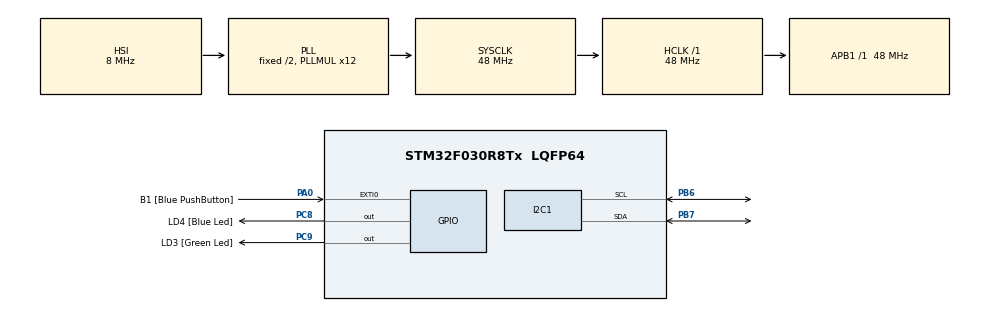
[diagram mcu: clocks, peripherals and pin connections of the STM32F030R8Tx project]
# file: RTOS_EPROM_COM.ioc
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FREERTOS.Tasks01=defaultTask,0,128,StartDefaultTask,Default,NULL,Dynamic,NULL,NULL
FREERTOS.configUSE_PREEMPTION=0
Mcu.Family=STM32F0
Mcu.Name=STM32F030R8Tx
Mcu.Package=LQFP64
NVIC.I2C1_IRQn=true\:3\:0\:false\:false\:true\:true\:true\:true
PA0.GPIO_Label=B1 [Blue PushButton]
PA0.GPIO_ModeDefaultEXTI=GPIO_MODE_EVT_RISING
PA0.Signal=GPXTI0
PA13.GPIO_Label=SWDIO
PA13.Mode=Serial_Wire
PA13.Signal=SYS_SWDIO
PA14.GPIO_Label=SWCLK
PA14.Mode=Serial_Wire
PA14.Signal=SYS_SWCLK
PB6.Mode=I2C
PB6.Signal=I2C1_SCL
PB7.Mode=I2C
PB7.Signal=I2C1_SDA
PC8.GPIO_Label=LD4 [Blue Led]
PC8.Signal=GPIO_Output
PC9.GPIO_Label=LD3 [Green Led]
PC9.Signal=GPIO_Output
ProjectManager.HeapSize=0x200
ProjectManager.StackSize=0x400
ProjectManager.TargetToolchain=STM32CubeIDE
RCC.AHBFreq_Value=48000000
RCC.APB1Freq_Value=48000000
RCC.APB1TimFreq_Value=48000000
RCC.HCLKFreq_Value=48000000
RCC.PLLMUL=RCC_PLL_MUL12
RCC.SYSCLKFreq_VALUE=48000000
RCC.SYSCLKSource=RCC_SYSCLKSOURCE_PLLCLK
VP_FREERTOS_VS_CMSIS_V1.Mode=CMSIS_V1
board=STM32F0308-DISCO

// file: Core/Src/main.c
/**
  ******************************************************************************
  * @file           : main.c
  * @brief          : Main program body
  ******************************************************************************
  * @attention
  *
  * <h2><center>&copy; Copyright (c) 2020 STMicroelectronics.
  * All rights reserved.</center></h2>
  *
  * This software component is licensed by ST under BSD 3-Clause license,
  * the "License"; You may not use this file except in compliance with the
  * License. You may obtain a copy of the License at:
  *                        opensource.org/licenses/BSD-3-Clause
  *
  ******************************************************************************
  */

#include "main.h"
#include "cmsis_os.h"

I2C_HandleTypeDef hi2c1;

osThreadId defaultTaskHandle;
/* USER CODE BEGIN PV */
osThreadId defaultTaskHandle1;
osThreadId defaultTaskHandle2;
/* USER CODE END PV */

void SystemClock_Config(void);
static void MX_GPIO_Init(void);
static void MX_I2C1_Init(void);
void StartDefaultTask(void const * argument);
void i2c_write(void);
void i2c_read(void);

uint8_t data[3] = {1,2,3};
uint8_t RX_data[3] = {0};
uint8_t data1[3] = {4,5,6};
uint8_t RX_data1[3] = {0};

osMutexId mutex_id;

int main(void)
{

  /* MCU Configuration--------------------------------------------------------*/

  /* Reset of all peripherals, Initializes the Flash interface and the Systick. */
  HAL_Init();

  /* Configure the system clock */
  SystemClock_Config();

  /* Initialize all configured peripherals */
  MX_GPIO_Init();
  MX_I2C1_Init();

  /* add mutexes, ... */
  osMutexDef(mutex);
  //osMutexDef_t *mutex;
  mutex_id = osMutexCreate(osMutex(mutex));

  osThreadDef(task1, i2c_write, osPriorityNormal, 0, 128);
  defaultTaskHandle1 = osThreadCreate(osThread(task1), NULL);

  osThreadDef(task2, i2c_read, osPriorityNormal, 0, 128);
  defaultTaskHandle2 = osThreadCreate(osThread(task2), NULL);

  /* Start scheduler */
  osKernelStart();

  while (1)
  {
  }

}

void i2c_write()
{
	while(1)
	{
	osMutexWait(mutex_id, 300);

	 if (HAL_I2C_Mem_Write_IT(&hi2c1, (uint16_t)0xa0, 0x10, 1, data,3)!= HAL_OK)
	 {

		 Error_Handler();
	 }
	HAL_Delay(1000);

	if (HAL_I2C_Mem_Write_IT(&hi2c1, (uint16_t)0xa0, 0x30, 1, data1,3)!= HAL_OK)
	{
		 Error_Handler();
	}

	osMutexRelease(mutex_id);
	}

}

void i2c_read()
{
	while(1)
	{
	osMutexWait(mutex_id, 300);
	if (HAL_I2C_Mem_Read_IT(&hi2c1, (uint16_t)0xa1, 0x10, 1, RX_data,3)!= HAL_OK)
	{
		 Error_Handler();
	}
	HAL_Delay(1000);

	if (HAL_I2C_Mem_Read_IT(&hi2c1, (uint16_t)0xa1, 0x30, 1, RX_data1,3)!= HAL_OK)
	{
		 Error_Handler();
	}
	osMutexRelease(mutex_id);
	}
}

void SystemClock_Config(void)
{
  RCC_OscInitTypeDef RCC_OscInitStruct = {0};
  RCC_ClkInitTypeDef RCC_ClkInitStruct = {0};
  RCC_PeriphCLKInitTypeDef PeriphClkInit = {0};

  /** Initializes the CPU, AHB and APB busses clocks
  */
  RCC_OscInitStruct.OscillatorType = RCC_OSCILLATORTYPE_HSI;
  RCC_OscInitStruct.HSIState = RCC_HSI_ON;
  RCC_OscInitStruct.HSICalibrationValue = RCC_HSICALIBRATION_DEFAULT;
  RCC_OscInitStruct.PLL.PLLState = RCC_PLL_ON;
  RCC_OscInitStruct.PLL.PLLSource = RCC_PLLSOURCE_HSI;
  RCC_OscInitStruct.PLL.PLLMUL = RCC_PLL_MUL12;
  RCC_OscInitStruct.PLL.PREDIV = RCC_PREDIV_DIV1;
  if (HAL_RCC_OscConfig(&RCC_OscInitStruct) != HAL_OK)
  {
    Error_Handler();
  }
  /** Initializes the CPU, AHB and APB busses clocks
  */
  RCC_ClkInitStruct.ClockType = RCC_CLOCKTYPE_HCLK|RCC_CLOCKTYPE_SYSCLK
                              |RCC_CLOCKTYPE_PCLK1;
  RCC_ClkInitStruct.SYSCLKSource = RCC_SYSCLKSOURCE_PLLCLK;
  RCC_ClkInitStruct.AHBCLKDivider = RCC_SYSCLK_DIV1;
  RCC_ClkInitStruct.APB1CLKDivider = RCC_HCLK_DIV1;

  if (HAL_RCC_ClockConfig(&RCC_ClkInitStruct, FLASH_LATENCY_1) != HAL_OK)
  {
    Error_Handler();
  }
  PeriphClkInit.PeriphClockSelection = RCC_PERIPHCLK_I2C1;
  PeriphClkInit.I2c1ClockSelection = RCC_I2C1CLKSOURCE_HSI;
  if (HAL_RCCEx_PeriphCLKConfig(&PeriphClkInit) != HAL_OK)
  {
    Error_Handler();
  }
}

static void MX_I2C1_Init(void)
{

  hi2c1.Instance = I2C1;
  hi2c1.Init.Timing = 0x2000090E;
  hi2c1.Init.OwnAddress1 = 0;
  hi2c1.Init.AddressingMode = I2C_ADDRESSINGMODE_7BIT;
  hi2c1.Init.DualAddressMode = I2C_DUALADDRESS_DISABLE;
  hi2c1.Init.OwnAddress2 = 0;
  hi2c1.Init.OwnAddress2Masks = I2C_OA2_NOMASK;
  hi2c1.Init.GeneralCallMode = I2C_GENERALCALL_DISABLE;
  hi2c1.Init.NoStretchMode = I2C_NOSTRETCH_DISABLE;
  if (HAL_I2C_Init(&hi2c1) != HAL_OK)
  {
    Error_Handler();
  }
  /** Configure Analogue filter
  */
  if (HAL_I2CEx_ConfigAnalogFilter(&hi2c1, I2C_ANALOGFILTER_ENABLE) != HAL_OK)
  {
    Error_Handler();
  }
  /** Configure Digital filter
  */
  if (HAL_I2CEx_ConfigDigitalFilter(&hi2c1, 0) != HAL_OK)
  {
    Error_Handler();
  }

}

static void MX_GPIO_Init(void)
{
  GPIO_InitTypeDef GPIO_InitStruct = {0};

  /* GPIO Ports Clock Enable */
  __HAL_RCC_GPIOA_CLK_ENABLE();
  __HAL_RCC_GPIOC_CLK_ENABLE();
  __HAL_RCC_GPIOB_CLK_ENABLE();

  /*Configure GPIO pin Output Level */
  HAL_GPIO_WritePin(GPIOC, LD4_Pin|LD3_Pin, GPIO_PIN_RESET);

  /*Configure GPIO pin : B1_Pin */
  GPIO_InitStruct.Pin = B1_Pin;
  GPIO_InitStruct.Mode = GPIO_MODE_EVT_RISING;
  GPIO_InitStruct.Pull = GPIO_NOPULL;
  HAL_GPIO_Init(B1_GPIO_Port, &GPIO_InitStruct);

  /*Configure GPIO pins : LD4_Pin LD3_Pin */
  GPIO_InitStruct.Pin = LD4_Pin|LD3_Pin;
  GPIO_InitStruct.Mode = GPIO_MODE_OUTPUT_PP;
  GPIO_InitStruct.Pull = GPIO_NOPULL;
  GPIO_InitStruct.Speed = GPIO_SPEED_FREQ_LOW;
  HAL_GPIO_Init(GPIOC, &GPIO_InitStruct);

}

void StartDefaultTask(void const * argument)
{
  /* Infinite loop */
  for(;;)
  {
    osDelay(1);
  }

}

void Error_Handler(void)
{
 ;
}

/************************ (C) COPYRIGHT STMicroelectronics *****END OF FILE****/
